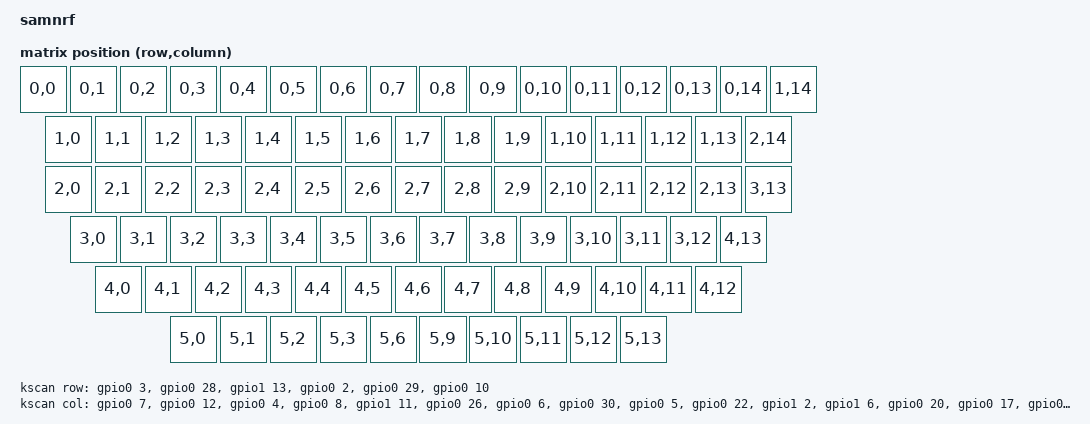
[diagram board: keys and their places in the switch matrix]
// This file was generated from a template. Edit it to match your keyboard.
// See https://docs.zephyrproject.org/3.5.0/hardware/porting/board_porting.html
// and https://zmk.dev/docs/development/hardware-integration/new-shield for more
// instructions.

/dts-v1/;
#include <nordic/nrf52840_qiaa.dtsi>
#include <dt-bindings/zmk/matrix_transform.h>

#include "samnrf-pinctrl.dtsi"
#include "samnrf-layouts.dtsi"

/ {
    model = "samnrf";
    compatible = "samnrf";

    chosen {
        zephyr,code-partition = &code_partition;
        zephyr,console = &cdc_acm_uart;
        zephyr,sram = &sram0;
        zephyr,flash = &flash0;
        // Uncomment this if you enabled one of the "vddh" nodes below.
        // zmk,battery = &vbatt;
        zmk,physical-layout = &default_layout;
    };

    kscan: kscan {
        // If the hardware does not use a switch matrix, change this to the
        // appropriate driver and update the properties below to match.
        // See https://zmk.dev/docs/config/kscan for supported key scan drivers.
        compatible = "zmk,kscan-gpio-matrix";
        // Set this to "col2row" or "row2col" to match the hardware. If using
        // "row2col", change the col-gpios to (GPIO_ACTIVE_HIGH | GPIO_PULL_DOWN)
        // and the row-gpios to GPIO_ACTIVE_HIGH.
        diode-direction = "col2row";
        wakeup-source;

        // Replace these comments with the GPIO pins in the matrix.
        // See https://zmk.dev/docs/development/hardware-integration/new-shield#shield-overlays
        col-gpios
            = <&gpio0 7 GPIO_ACTIVE_HIGH>
            , <&gpio0 12 GPIO_ACTIVE_HIGH>
            , <&gpio0 4 GPIO_ACTIVE_HIGH>
            , <&gpio0 8 GPIO_ACTIVE_HIGH>
            , <&gpio1 11 GPIO_ACTIVE_HIGH>
            , <&gpio0 26 GPIO_ACTIVE_HIGH>
            , <&gpio0 6 GPIO_ACTIVE_HIGH>
            , <&gpio0 30 GPIO_ACTIVE_HIGH>
            , <&gpio0 5 GPIO_ACTIVE_HIGH>
            , <&gpio0 22 GPIO_ACTIVE_HIGH>
            , <&gpio1 2 GPIO_ACTIVE_HIGH>
            , <&gpio1 6 GPIO_ACTIVE_HIGH>
            , <&gpio0 20 GPIO_ACTIVE_HIGH>
            , <&gpio0 17 GPIO_ACTIVE_HIGH>
            , <&gpio0 15 GPIO_ACTIVE_HIGH>
            ;

        row-gpios
            = <&gpio0 3 (GPIO_ACTIVE_HIGH | GPIO_PULL_DOWN)>
            , <&gpio0 28 (GPIO_ACTIVE_HIGH | GPIO_PULL_DOWN)>
            , <&gpio1 13 (GPIO_ACTIVE_HIGH | GPIO_PULL_DOWN)>
            , <&gpio0 2 (GPIO_ACTIVE_HIGH | GPIO_PULL_DOWN)>
            , <&gpio0 29 (GPIO_ACTIVE_HIGH | GPIO_PULL_DOWN)>
            , <&gpio0 10 (GPIO_ACTIVE_HIGH | GPIO_PULL_DOWN)>
            ;
    };

    default_transform: default_transform {
        // See https://zmk.dev/docs/development/hardware-integration/new-shield#matrix-transform
        // for how to configure this
        compatible = "zmk,matrix-transform";
        columns = <15>;
        rows = <6>;

        // | MX1 | MX7  | MX13 | MX19 | MX25 | MX30 | MX35 | MX41 | MX46 | MX51 | MX57 | MX63 | MX69 | MX75 | MX80 |    | MX81 |
        // | MX2 | MX8  | MX14 | MX20 | MX26 | MX31 | MX36 | MX42 | MX47 | MX52 | MX58 | MX64 | MX70 |     MX76    |    | MX82 |
        // |  MX3  | MX9  | MX15 | MX21 | MX27 | MX32 | MX37 | MX43 | MX48 | MX53 | MX59 | MX65 | MX71 |   MX77    |    | MX79 |
        // |   MX4   | MX10 | MX16 | MX22 | MX28 | MX33 | MX38 | MX44 | MX49 | MX54 | MX60 | MX66 |      MX72      |    | MX83 |
        // |    MX5    | MX11 | MX17 | MX23 | MX29 | MX34 | MX39 | MX45 | MX50 | MX55 | MX61 | MX67 |    MX73    | MX73 |
        // |  MX6  |  MX12  |  MX18  |  MX24  |                 MX40                  |   MX56   |   MX62 | MX68 | MX74 | MX78 |

        map = <
            RC(0,0) RC(0,1) RC(0,2) RC(0,3) RC(0,4) RC(0,5) RC(0,6) RC(0,7) RC(0,8) RC(0,9) RC(0,10) RC(0,11) RC(0,12) RC(0,13) RC(0,14)      RC(1,14)
            RC(1,0) RC(1,1) RC(1,2) RC(1,3) RC(1,4) RC(1,5) RC(1,6) RC(1,7) RC(1,8) RC(1,9) RC(1,10) RC(1,11) RC(1,12)      RC(1,13)          RC(2,14)
            RC(2,0)    RC(2,1) RC(2,2) RC(2,3) RC(2,4) RC(2,5) RC(2,6) RC(2,7) RC(2,8) RC(2,9) RC(2,10) RC(2,11) RC(2,12)   RC(2,13)          RC(3,13)
            RC(3,0)     RC(3,1) RC(3,2) RC(3,3) RC(3,4) RC(3,5) RC(3,6) RC(3,7) RC(3,8) RC(3,9) RC(3,10) RC(3,11)          RC(3,12)           RC(4,13)
            RC(4,0)       RC(4,1) RC(4,2) RC(4,3) RC(4,4) RC(4,5) RC(4,6) RC(4,7) RC(4,8) RC(4,9) RC(4,10)                RC(4,11)   RC(4,12) 
            RC(5,0)    RC(5,1)   RC(5,2)   RC(5,3)                     RC(5,6)                    RC(5,9)    RC(5,10)       RC(5,11) RC(5,12) RC(5,13)
        >;
    };

    leds {
        compatible = "gpio-leds";

        // If you have a GPIO routed to a status LED, set it here.
        // Otherwise, delete this block.
        blue_led: led_0 {
            gpios = <&gpio0 0 GPIO_ACTIVE_HIGH>;
        };
    };

    // If you are powering the SoC from the VDDH pin, uncomment this block.
    // Otherwise, delete it.

    // vbatt: vbatt {
    //     compatible = "zmk,battery-nrf-vddh";
    // };

    // If you are powering the SoC from the VDD pin and you have a voltage divider
    // routed to an analog pin to read the battery voltage, uncomment this block
    // and assign the correct ADC channel and resistance values.
    // Otherwise, delete it.

    // vbatt: vbatt {
    //     compatible = "voltage-divider";
    //     io-channels = <&adc 2>;
    //     output-ohms = <2000000>;
    //     full-ohms = <(2000000 + 806000)>;
    // };

    vbatt: vbatt {
        compatible = "zmk,battery-voltage-divider";
        label = "BATTERY";
        io-channels = <&adc 7>;
        output-ohms = <2000000>;
        full-ohms = <(2000000 + 806000)>;
    };

};

&adc {
    status = "okay";
};

&gpiote {
    status = "okay";
};

&gpio0 {
    status = "okay";
};

&gpio1 {
    status = "okay";
};

//&uart0 {
//    compatible = "nordic,nrf-uarte";
//    current-speed = <115200>;
//    pinctrl-0 = <&uart0_default>;
//    pinctrl-1 = <&uart0_sleep>;
//    pinctrl-names = "default", "sleep";
//};

&usbd {
    status = "okay";
    cdc_acm_uart: cdc_acm_uart {
        compatible = "zephyr,cdc-acm-uart";
        label = "CDC_ACM_0";
    };
};

zephyr_udc0: &usbd {
    status = "okay";
};

&flash0 {
    /*
     * For more information, see:
     * http://docs.zephyrproject.org/latest/devices/dts/flash_partitions.html
     */
    partitions {
        compatible = "fixed-partitions";
        #address-cells = <1>;
        #size-cells = <1>;

        sd_partition: partition@0 {
            label = "mbr";
            reg = <0x00000000 0x00001000>;
        };

        code_partition: partition@1000 {
            label = "code_partition";
            reg = <0x00001000 0x000d3000>;
        };

        /*
         * The flash starting at 0x000d4000 and ending at
         * 0x000f3fff is reserved for use by the application.
         */

        /*
         * Storage partition will be used by FCB/LittleFS/NVS
         * if enabled.
         */
        storage_partition: partition@d4000 {
            label = "storage";
            reg = <0x000d4000 0x00020000>;
        };

        boot_partition: partition@f4000 {
            label = "adafruit_boot";
            reg = <0x000f4000 0x0000c000>;
        };
    };
};

// &flash0 {
//     // Adjust this flash map as is necessary for your board. For more information, see
//     // https://docs.zephyrproject.org/3.5.0/services/storage/flash_map/flash_map.html#relationship-with-devicetree
//     partitions {
//         compatible = "fixed-partitions";
//         #address-cells = <1>;
//         #size-cells = <1>;

//         code_partition: partition@1000 {
//             reg = <DT_SIZE_K(4) DT_SIZE_K(844)>;
//         };

//         // If using a bootloader with SoftDevice included, replace the code_partition
//         // node above with the following. If using SoftDevice v7, change 26000 to 27000.

//         // sd_partition: partition@0 {
//         //     reg = <0x0 <DT_SIZE_K(4)>;
//         // };
//         // code_partition: partition@26000 {
//         //     reg = <DT_SIZE_K(152) DT_SIZE_K(792)>;
//         // };

//         // The flash starting at 0x000d4000 and ending at
//         // 0x000f3fff is reserved for use by the application.

//         // Storage partition will be used by NVS if enabled.
//         storage_partition: partition@d4000 {
//             reg = <DT_SIZE_K(848) DT_SIZE_K(128)>;
//         };

//         boot_partition: partition@f4000 {
//             reg = <DT_SIZE_K(976) DT_SIZE_K(48)>;
//         };
//     };
// };
